AUTOSAR XML (schema 4-2-2)
package /ComponentTypes
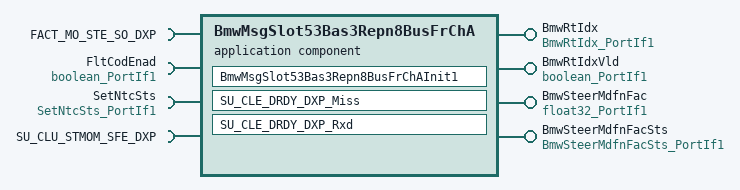
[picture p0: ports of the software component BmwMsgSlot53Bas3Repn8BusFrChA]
  application sw component type BmwMsgSlot53Bas3Repn8BusFrChA
    4 x provide port:
      BmwRtIdx: nonqueued-sender-com-spec{data-element=Val, init-value=15}, provided-interface=BmwRtIdx_PortIf1
      BmwRtIdxVld: nonqueued-sender-com-spec{data-element=Logl, init-value=0}, provided-interface=boolean_PortIf1
      BmwSteerMdfnFac: nonqueued-sender-com-spec{data-element=Val, init-value=0}, provided-interface=float32_PortIf1
      BmwSteerMdfnFacSts: nonqueued-sender-com-spec{data-element=Val, init-value=4}, provided-interface=BmwSteerMdfnFacSts_PortIf1
    4 x require port:
      FACT_MO_STE_SO_DXP: nonqueued-receiver-com-spec{data-element=FACT_MO_STE_SO_DXP, uses-end-to-end-protection=true, alive-timeout=0.045, enable-update=true, filter=data-filter-type=ALWAYS, init-value=255}, required-interface=FACT_MO_STE_SO_DXP
      FltCodEnad: nonqueued-receiver-com-spec{data-element=Logl, filter=data-filter-type=ALWAYS, init-value=1}, required-interface=boolean_PortIf1
      SetNtcSts: client-com-spec=Oper, required-interface=SetNtcSts_PortIf1
      SU_CLU_STMOM_SFE_DXP: nonqueued-receiver-com-spec{data-element=SU_CLU_STMOM_SFE_DXP, alive-timeout=0.045, filter=data-filter-type=ALWAYS, init-value=15}, required-interface=SU_CLU_STMOM_SFE_DXP
    behavior BmwMsgSlot53Bas3Repn8BusFrChA_InternalBehavior
      ar-typed-per-instance-memorys:
        9 x data, all with sw-calibration-access=READ-ONLY:
          BmwRtIdxPrev: type=BmwRtIdx1
          BmwSteerMdfnFacPrev: type=float32
          BmwSteerMdfnFacStsPrev: type=BmwSteerMdfnFacSts1
          FactMoSteSoDxpVldFaild: type=uint8
          FactMoSteSoDxpVldPassd: type=uint8
          MissMsgFaild: type=uint8
          MissMsgPassd: type=uint8
          SuCluStmomSfeDxpVldFaild: type=uint8
          SuCluStmomSfeDxpVldPassd: type=uint8
      init event BmwMsgSlot53Bas3Repn8BusFrChAInit1_InitEvent: start-on-event=BmwMsgSlot53Bas3Repn8BusFrChAInit1
      data receive error event DRET_SU_CLE_DRDY_DXP_Miss_FACT_MO_STE_SO_DXP_FACT_MO_STE_SO_DXP: start-on-event=SU_CLE_DRDY_DXP_Miss, data=FACT_MO_STE_SO_DXP.FACT_MO_STE_SO_DXP
      data receive error event DRET_SU_CLE_DRDY_DXP_Miss_SU_CLU_STMOM_SFE_DXP_SU_CLU_STMOM_SFE_DXP: start-on-event=SU_CLE_DRDY_DXP_Miss, data=SU_CLU_STMOM_SFE_DXP.SU_CLU_STMOM_SFE_DXP
      data received event DRT_SU_CLE_DRDY_DXP_Rxd_FACT_MO_STE_SO_DXP_FACT_MO_STE_SO_DXP: start-on-event=SU_CLE_DRDY_DXP_Rxd, data=FACT_MO_STE_SO_DXP.FACT_MO_STE_SO_DXP
      data received event DRT_SU_CLE_DRDY_DXP_Rxd_SU_CLU_STMOM_SFE_DXP_SU_CLU_STMOM_SFE_DXP: start-on-event=SU_CLE_DRDY_DXP_Rxd, data=SU_CLU_STMOM_SFE_DXP.SU_CLU_STMOM_SFE_DXP
      port-api-options:
        enable-take-address=false, error-handling=NO-TRANSFORMER-ERROR-HANDLING, indirect-api=false, port=BmwRtIdx
        enable-take-address=false, error-handling=NO-TRANSFORMER-ERROR-HANDLING, indirect-api=false, port=BmwRtIdxVld
        enable-take-address=false, error-handling=NO-TRANSFORMER-ERROR-HANDLING, indirect-api=false, port=BmwSteerMdfnFac
        enable-take-address=false, error-handling=NO-TRANSFORMER-ERROR-HANDLING, indirect-api=false, port=BmwSteerMdfnFacSts
        enable-take-address=false, error-handling=NO-TRANSFORMER-ERROR-HANDLING, indirect-api=false, port=FACT_MO_STE_SO_DXP
        enable-take-address=false, error-handling=NO-TRANSFORMER-ERROR-HANDLING, indirect-api=false, port=FltCodEnad
        enable-take-address=false, error-handling=NO-TRANSFORMER-ERROR-HANDLING, indirect-api=false, port=SetNtcSts
        enable-take-address=false, error-handling=NO-TRANSFORMER-ERROR-HANDLING, indirect-api=false, port=SU_CLU_STMOM_SFE_DXP
      runnable BmwMsgSlot53Bas3Repn8BusFrChAInit1
        data-receive-point-by-arguments:
          access REC_FACT_MO_STE_SO_DXP_FACT_MO_STE_SO_DXP: accessed-variable=FACT_MO_STE_SO_DXP.FACT_MO_STE_SO_DXP
          access REC_FltCodEnad_Logl: accessed-variable=FltCodEnad.Logl
          access REC_SU_CLU_STMOM_SFE_DXP_SU_CLU_STMOM_SFE_DXP: accessed-variable=SU_CLU_STMOM_SFE_DXP.SU_CLU_STMOM_SFE_DXP
        data-send-points:
          4 x access:
            SEND_BmwRtIdx_Val: accessed-variable=BmwRtIdx.Val
            SEND_BmwRtIdxVld_Logl: accessed-variable=BmwRtIdxVld.Logl
            SEND_BmwSteerMdfnFac_Val: accessed-variable=BmwSteerMdfnFac.Val
            SEND_BmwSteerMdfnFacSts_Val: accessed-variable=BmwSteerMdfnFacSts.Val
        sync call SC_SetNtcSts_Oper: operation=SetNtcSts.Oper, timeout=0
      runnable SU_CLE_DRDY_DXP_Miss
        data-receive-point-by-arguments:
          access REC_FltCodEnad_Logl: accessed-variable=FltCodEnad.Logl
        data-send-points:
          4 x access:
            SEND_BmwRtIdx_Val: accessed-variable=BmwRtIdx.Val
            SEND_BmwRtIdxVld_Logl: accessed-variable=BmwRtIdxVld.Logl
            SEND_BmwSteerMdfnFac_Val: accessed-variable=BmwSteerMdfnFac.Val
            SEND_BmwSteerMdfnFacSts_Val: accessed-variable=BmwSteerMdfnFacSts.Val
        sync call SC_SetNtcSts_Oper: operation=SetNtcSts.Oper, timeout=0
      runnable SU_CLE_DRDY_DXP_Rxd
        data-receive-point-by-arguments:
          access REC_FACT_MO_STE_SO_DXP_FACT_MO_STE_SO_DXP: accessed-variable=FACT_MO_STE_SO_DXP.FACT_MO_STE_SO_DXP
          access REC_FltCodEnad_Logl: accessed-variable=FltCodEnad.Logl
          access REC_SU_CLU_STMOM_SFE_DXP_SU_CLU_STMOM_SFE_DXP: accessed-variable=SU_CLU_STMOM_SFE_DXP.SU_CLU_STMOM_SFE_DXP
        data-send-points:
          4 x access:
            SEND_BmwRtIdx_Val: accessed-variable=BmwRtIdx.Val
            SEND_BmwRtIdxVld_Logl: accessed-variable=BmwRtIdxVld.Logl
            SEND_BmwSteerMdfnFac_Val: accessed-variable=BmwSteerMdfnFac.Val
            SEND_BmwSteerMdfnFacSts_Val: accessed-variable=BmwSteerMdfnFacSts.Val
        sync call SC_SetNtcSts_Oper: operation=SetNtcSts.Oper, timeout=0
  swc implementation BmwMsgSlot53Bas3Repn8BusFrChA_Implementation: behavior=BmwMsgSlot53Bas3Repn8BusFrChA_InternalBehavior
    code-descriptors:
      code Default: artifact-descriptors=autosar-engineering-object={short-label=Default, category=SWSRC}
